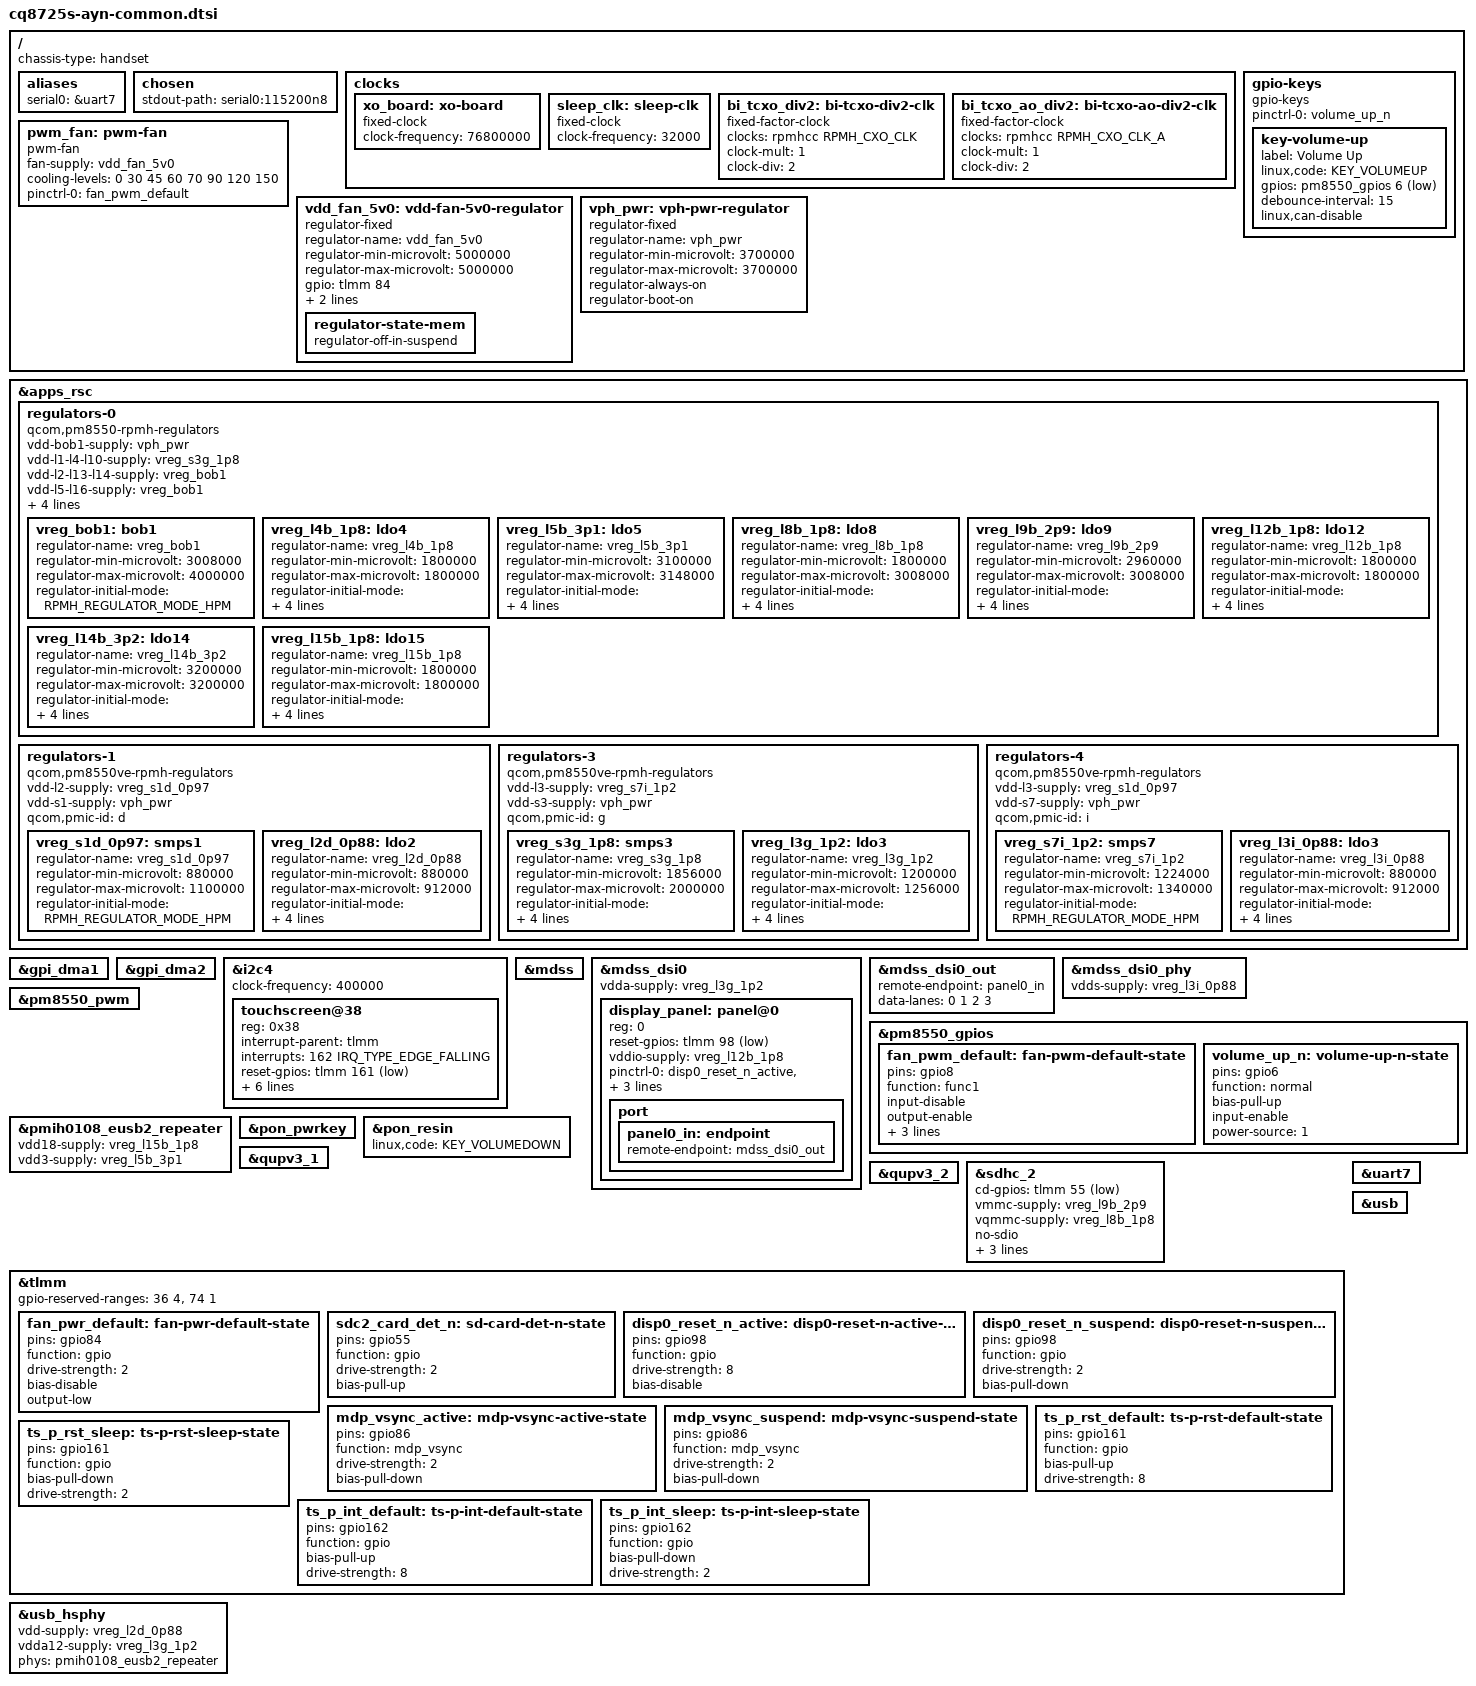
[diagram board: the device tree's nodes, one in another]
// SPDX-License-Identifier: BSD-3-Clause
/*
 * Copyright (c) 2026 Teguh Sobirin.
 * Copyright (c) 2026 Armada contributors.
 */

/dts-v1/;

#include <dt-bindings/gpio/gpio.h>
#include <dt-bindings/input/input.h>
#include <dt-bindings/regulator/qcom,rpmh-regulator.h>
#include "sm8750.dtsi"
#include "pm8550.dtsi"
#define PMK8550VE_SID 8
#include "pm8550ve.dtsi"
#include "pmih0108.dtsi"
#include "pmk8550.dtsi"
#include "sm8750-pmics.dtsi"

/ {
	chassis-type = "handset";

	aliases {
		serial0 = &uart7;
	};

	chosen {
		stdout-path = "serial0:115200n8";
	};

	clocks {
		xo_board: xo-board {
			compatible = "fixed-clock";
			clock-frequency = <76800000>;
			#clock-cells = <0>;
		};

		sleep_clk: sleep-clk {
			compatible = "fixed-clock";
			clock-frequency = <32000>;
			#clock-cells = <0>;
		};

		bi_tcxo_div2: bi-tcxo-div2-clk {
			compatible = "fixed-factor-clock";
			#clock-cells = <0>;

			clocks = <&rpmhcc RPMH_CXO_CLK>;
			clock-mult = <1>;
			clock-div = <2>;
		};

		bi_tcxo_ao_div2: bi-tcxo-ao-div2-clk {
			compatible = "fixed-factor-clock";
			#clock-cells = <0>;

			clocks = <&rpmhcc RPMH_CXO_CLK_A>;
			clock-mult = <1>;
			clock-div = <2>;
		};
	};

	pwm_fan: pwm-fan {
		compatible = "pwm-fan";

		fan-supply = <&vdd_fan_5v0>;

		#cooling-cells = <2>;
		cooling-levels = <0 30 45 60 70 90 120 150>;
		pinctrl-names = "default";
		pinctrl-0 = <&fan_pwm_default>;
	};

	gpio-keys {
		compatible = "gpio-keys";

		pinctrl-0 = <&volume_up_n>;
		pinctrl-names = "default";

		key-volume-up {
			label = "Volume Up";
			linux,code = <KEY_VOLUMEUP>;
			gpios = <&pm8550_gpios 6 GPIO_ACTIVE_LOW>;
			debounce-interval = <15>;
			linux,can-disable;
		};
	};

	vdd_fan_5v0: vdd-fan-5v0-regulator {
		compatible = "regulator-fixed";
		regulator-name = "vdd_fan_5v0";

		regulator-min-microvolt = <5000000>;
		regulator-max-microvolt = <5000000>;

		gpio = <&tlmm 84 GPIO_ACTIVE_HIGH>;
		enable-active-high;

		pinctrl-names = "default";
		pinctrl-0 = <&fan_pwr_default>;

		regulator-state-mem {
			regulator-off-in-suspend;
		};
	};

	vph_pwr: vph-pwr-regulator {
		compatible = "regulator-fixed";

		regulator-name = "vph_pwr";
		regulator-min-microvolt = <3700000>;
		regulator-max-microvolt = <3700000>;

		regulator-always-on;
		regulator-boot-on;
	};
};

&apps_rsc {
	regulators-0 {
		compatible = "qcom,pm8550-rpmh-regulators";

		vdd-bob1-supply = <&vph_pwr>;
		vdd-l1-l4-l10-supply = <&vreg_s3g_1p8>;
		vdd-l2-l13-l14-supply = <&vreg_bob1>;
		vdd-l5-l16-supply = <&vreg_bob1>;
		vdd-l8-l9-supply = <&vreg_bob1>;
		vdd-l12-supply = <&vreg_s3g_1p8>;
		vdd-l15-supply = <&vreg_s3g_1p8>;

		qcom,pmic-id = "b";

		vreg_bob1: bob1 {
			regulator-name = "vreg_bob1";
			regulator-min-microvolt = <3008000>;
			regulator-max-microvolt = <4000000>;
			regulator-initial-mode = <RPMH_REGULATOR_MODE_HPM>;
		};

		vreg_l4b_1p8: ldo4 {
			regulator-name = "vreg_l4b_1p8";
			regulator-min-microvolt = <1800000>;
			regulator-max-microvolt = <1800000>;
			regulator-initial-mode = <RPMH_REGULATOR_MODE_HPM>;
			regulator-allow-set-load;
			regulator-allowed-modes = <RPMH_REGULATOR_MODE_LPM
						   RPMH_REGULATOR_MODE_HPM>;
		};

		vreg_l5b_3p1: ldo5 {
			regulator-name = "vreg_l5b_3p1";
			regulator-min-microvolt = <3100000>;
			regulator-max-microvolt = <3148000>;
			regulator-initial-mode = <RPMH_REGULATOR_MODE_HPM>;
			regulator-allow-set-load;
			regulator-allowed-modes = <RPMH_REGULATOR_MODE_LPM
						   RPMH_REGULATOR_MODE_HPM>;
		};

		vreg_l8b_1p8: ldo8 {
			regulator-name = "vreg_l8b_1p8";
			regulator-min-microvolt = <1800000>;
			regulator-max-microvolt = <3008000>;
			regulator-initial-mode = <RPMH_REGULATOR_MODE_HPM>;
			regulator-allow-set-load;
			regulator-allowed-modes = <RPMH_REGULATOR_MODE_LPM
						   RPMH_REGULATOR_MODE_HPM>;
		};

		vreg_l9b_2p9: ldo9 {
			regulator-name = "vreg_l9b_2p9";
			regulator-min-microvolt = <2960000>;
			regulator-max-microvolt = <3008000>;
			regulator-initial-mode = <RPMH_REGULATOR_MODE_HPM>;
			regulator-allow-set-load;
			regulator-allowed-modes = <RPMH_REGULATOR_MODE_LPM
						   RPMH_REGULATOR_MODE_HPM>;
		};

		vreg_l12b_1p8: ldo12 {
			regulator-name = "vreg_l12b_1p8";
			regulator-min-microvolt = <1800000>;
			regulator-max-microvolt = <1800000>;
			regulator-initial-mode = <RPMH_REGULATOR_MODE_HPM>;
			regulator-allow-set-load;
			regulator-allowed-modes = <RPMH_REGULATOR_MODE_LPM
						   RPMH_REGULATOR_MODE_HPM>;
		};

		vreg_l14b_3p2: ldo14 {
			regulator-name = "vreg_l14b_3p2";
			regulator-min-microvolt = <3200000>;
			regulator-max-microvolt = <3200000>;
			regulator-initial-mode = <RPMH_REGULATOR_MODE_HPM>;
			regulator-allow-set-load;
			regulator-allowed-modes = <RPMH_REGULATOR_MODE_LPM
						   RPMH_REGULATOR_MODE_HPM>;
		};

		vreg_l15b_1p8: ldo15 {
			regulator-name = "vreg_l15b_1p8";
			regulator-min-microvolt = <1800000>;
			regulator-max-microvolt = <1800000>;
			regulator-initial-mode = <RPMH_REGULATOR_MODE_HPM>;
			regulator-allow-set-load;
			regulator-allowed-modes = <RPMH_REGULATOR_MODE_LPM
						   RPMH_REGULATOR_MODE_HPM>;
		};
	};

	regulators-1 {
		compatible = "qcom,pm8550ve-rpmh-regulators";
		vdd-l2-supply = <&vreg_s1d_0p97>;
		vdd-s1-supply = <&vph_pwr>;

		qcom,pmic-id = "d";

		vreg_s1d_0p97: smps1 {
			regulator-name = "vreg_s1d_0p97";
			regulator-min-microvolt = <880000>;
			regulator-max-microvolt = <1100000>;
			regulator-initial-mode = <RPMH_REGULATOR_MODE_HPM>;
		};

		vreg_l2d_0p88: ldo2 {
			regulator-name = "vreg_l2d_0p88";
			regulator-min-microvolt = <880000>;
			regulator-max-microvolt = <912000>;
			regulator-initial-mode = <RPMH_REGULATOR_MODE_HPM>;
			regulator-allow-set-load;
			regulator-allowed-modes = <RPMH_REGULATOR_MODE_LPM
						   RPMH_REGULATOR_MODE_HPM>;
		};
	};

	regulators-3 {
		compatible = "qcom,pm8550ve-rpmh-regulators";
		vdd-l3-supply = <&vreg_s7i_1p2>;
		vdd-s3-supply = <&vph_pwr>;

		qcom,pmic-id = "g";

		vreg_s3g_1p8: smps3 {
			regulator-name = "vreg_s3g_1p8";
			regulator-min-microvolt = <1856000>;
			regulator-max-microvolt = <2000000>;
			regulator-initial-mode = <RPMH_REGULATOR_MODE_LPM>;
			regulator-allow-set-load;
			regulator-allowed-modes = <RPMH_REGULATOR_MODE_LPM
						   RPMH_REGULATOR_MODE_HPM>;
		};

		vreg_l3g_1p2: ldo3 {
			regulator-name = "vreg_l3g_1p2";
			regulator-min-microvolt = <1200000>;
			regulator-max-microvolt = <1256000>;
			regulator-initial-mode = <RPMH_REGULATOR_MODE_HPM>;
			regulator-allow-set-load;
			regulator-allowed-modes = <RPMH_REGULATOR_MODE_LPM
						   RPMH_REGULATOR_MODE_HPM>;
		};
	};

	regulators-4 {
		compatible = "qcom,pm8550ve-rpmh-regulators";
		vdd-l3-supply = <&vreg_s1d_0p97>;
		vdd-s7-supply = <&vph_pwr>;

		qcom,pmic-id = "i";

		vreg_s7i_1p2: smps7 {
			regulator-name = "vreg_s7i_1p2";
			regulator-min-microvolt = <1224000>;
			regulator-max-microvolt = <1340000>;
			regulator-initial-mode = <RPMH_REGULATOR_MODE_HPM>;
		};

		vreg_l3i_0p88: ldo3 {
			regulator-name = "vreg_l3i_0p88";
			regulator-min-microvolt = <880000>;
			regulator-max-microvolt = <912000>;
			regulator-initial-mode = <RPMH_REGULATOR_MODE_HPM>;
			regulator-allow-set-load;
			regulator-allowed-modes = <RPMH_REGULATOR_MODE_LPM
						   RPMH_REGULATOR_MODE_HPM>;
		};
	};
};

&gpi_dma1 {
	status = "okay";
};

&gpi_dma2 {
	status = "okay";
};

&i2c4 {
	clock-frequency = <400000>;
	status = "okay";

	touchscreen@38 {
		reg = <0x38>;

		interrupt-parent = <&tlmm>;
		interrupts = <162 IRQ_TYPE_EDGE_FALLING>;

		reset-gpios = <&tlmm 161 GPIO_ACTIVE_LOW>;

		vcc-supply = <&vreg_l14b_3p2>;
		iovcc-supply = <&vreg_l12b_1p8>;

		pinctrl-0 = <&ts_p_rst_default &ts_p_int_default>;
		pinctrl-1 = <&ts_p_rst_sleep &ts_p_int_sleep>;
		pinctrl-names = "default", "sleep";

		touchscreen-size-x = <1080>;
		touchscreen-size-y = <1920>;
	};
};

&mdss {
	status = "okay";
};

&mdss_dsi0 {
	vdda-supply = <&vreg_l3g_1p2>;

	status = "okay";

	display_panel: panel@0 {
		reg = <0>;

		reset-gpios = <&tlmm 98 GPIO_ACTIVE_LOW>;

		vddio-supply = <&vreg_l12b_1p8>;

		pinctrl-0 = <&disp0_reset_n_active>, <&mdp_vsync_active>;
		pinctrl-1 = <&disp0_reset_n_suspend>, <&mdp_vsync_suspend>;
		pinctrl-names = "default", "sleep";

		port {
			panel0_in: endpoint {
				remote-endpoint = <&mdss_dsi0_out>;
			};
		};
	};
};

&mdss_dsi0_out {
	remote-endpoint = <&panel0_in>;
	data-lanes = <0 1 2 3>;
};

&mdss_dsi0_phy {
	vdds-supply = <&vreg_l3i_0p88>;

	status = "okay";
};

&pm8550_gpios {
	fan_pwm_default: fan-pwm-default-state {
		pins = "gpio8";
		function = "func1";
		input-disable;
		output-enable;
		output-low;
		bias-disable;
		power-source = <1>;
	};

	volume_up_n: volume-up-n-state {
		pins = "gpio6";
		function = "normal";
		bias-pull-up;
		input-enable;
		power-source = <1>;
	};
};

&pm8550_pwm {
	status = "okay";
};

&pmih0108_eusb2_repeater {
	status = "okay";

	vdd18-supply = <&vreg_l15b_1p8>;
	vdd3-supply = <&vreg_l5b_3p1>;
};

&pon_pwrkey {
	status = "okay";
};

&pon_resin {
	linux,code = <KEY_VOLUMEDOWN>;

	status = "okay";
};

&qupv3_1 {
	status = "okay";
};

&qupv3_2 {
	status = "okay";
};

&sdhc_2 {
	cd-gpios = <&tlmm 55 GPIO_ACTIVE_LOW>;

	vmmc-supply = <&vreg_l9b_2p9>;
	vqmmc-supply = <&vreg_l8b_1p8>;

	no-sdio;
	no-mmc;

	pinctrl-0 = <&sdc2_default &sdc2_card_det_n>;
	pinctrl-1 = <&sdc2_sleep &sdc2_card_det_n>;
	pinctrl-names = "default", "sleep";

	status = "okay";
};

&tlmm {
	gpio-reserved-ranges = <36 4>, <74 1>;

	fan_pwr_default: fan-pwr-default-state {
		pins = "gpio84";
		function = "gpio";
		drive-strength = <2>;
		bias-disable;
		output-low;
	};

	sdc2_card_det_n: sd-card-det-n-state {
		pins = "gpio55";
		function = "gpio";
		drive-strength = <2>;
		bias-pull-up;
	};

	disp0_reset_n_active: disp0-reset-n-active-state {
		pins = "gpio98";
		function = "gpio";
		drive-strength = <8>;
		bias-disable;
	};

	disp0_reset_n_suspend: disp0-reset-n-suspend-state {
		pins = "gpio98";
		function = "gpio";
		drive-strength = <2>;
		bias-pull-down;
	};

	mdp_vsync_active: mdp-vsync-active-state {
		pins = "gpio86";
		function = "mdp_vsync";
		drive-strength = <2>;
		bias-pull-down;
	};

	mdp_vsync_suspend: mdp-vsync-suspend-state {
		pins = "gpio86";
		function = "mdp_vsync";
		drive-strength = <2>;
		bias-pull-down;
	};

	ts_p_rst_default: ts-p-rst-default-state {
		pins = "gpio161";
		function = "gpio";
		bias-pull-up;
		drive-strength = <8>;
	};

	ts_p_rst_sleep: ts-p-rst-sleep-state {
		pins = "gpio161";
		function = "gpio";
		bias-pull-down;
		drive-strength = <2>;
	};

	ts_p_int_default: ts-p-int-default-state {
		pins = "gpio162";
		function = "gpio";
		bias-pull-up;
		drive-strength = <8>;
	};

	ts_p_int_sleep: ts-p-int-sleep-state {
		pins = "gpio162";
		function = "gpio";
		bias-pull-down;
		drive-strength = <2>;
	};
};

&uart7 {
	status = "okay";
};

&usb {
	status = "okay";
};

&usb_hsphy {
	vdd-supply = <&vreg_l2d_0p88>;
	vdda12-supply = <&vreg_l3g_1p2>;

	phys = <&pmih0108_eusb2_repeater>;

	status = "okay";
};
